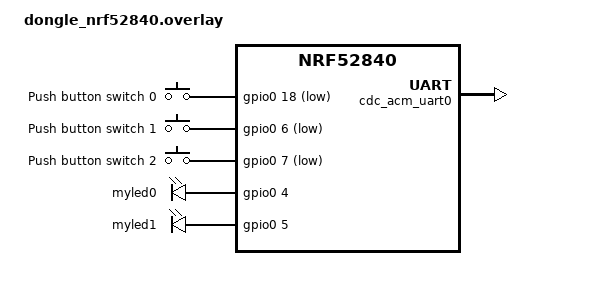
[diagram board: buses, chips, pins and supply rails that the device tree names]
/* Copyright (c) 2020 Nordic Semiconductor ASA
 *
 * SPDX-License-Identifier: LicenseRef-Nordic-5-Clause
 */

/ {
    /*
    * In some default configurations within the nRF Connect SDK,
    * e.g. on nRF52840, the chosen zephyr,entropy node is &cryptocell.
    * This devicetree overlay ensures that default is overridden wherever it
    * is set, as this application uses the RNG node for entropy exclusively.
    */
    chosen {
        zephyr,console = &cdc_acm_uart0;
        zephyr,entropy = &rng;
        zephyr,shell-uart = &cdc_acm_uart0;
    };
    aliases {
        line1 = &myled0;
        line2 = &myled1;
        row1 = &button1;
        row2 = &button2;
    };
    buttons {
        compatible = "gpio-keys";
        button0: button_0 {
            gpios = <&gpio0 18 (GPIO_PULL_UP | GPIO_ACTIVE_LOW)>;
            label = "Push button switch 0";
        };
        button1: button_1 {
            gpios = <&gpio0 6 (GPIO_PULL_UP | GPIO_ACTIVE_LOW)>;
            label = "Push button switch 1";
        };
        button2: button_2 {
            gpios = <&gpio0 7 (GPIO_PULL_UP | GPIO_ACTIVE_LOW)>;
            label = "Push button switch 2";
        };
    };

    leds {
            compatible = "gpio-leds";
            myled0: led_4 {
                    gpios = <&gpio0 4 GPIO_ACTIVE_HIGH>;
            };
            myled1: led_5 {
                gpios = <&gpio0 5 GPIO_ACTIVE_HIGH>;
        };
    };
};

&adc {
    status = "disabled";
};
&uart1 {
    status = "disabled";
};
&pwm0 {
    status = "disabled";
};
&i2c0 {
    status = "disabled";
};
&spi0 {
    status = "disabled";
};
&spi1 {
    status = "disabled";
};
&spi2 {
    status = "disabled";
};
&spi3 {
    status = "disabled";
};
&qspi {
    status = "disabled";
};

&zephyr_udc0 {
    cdc_acm_uart0: cdc_acm_uart0 {
        compatible = "zephyr,cdc-acm-uart";
    };
};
